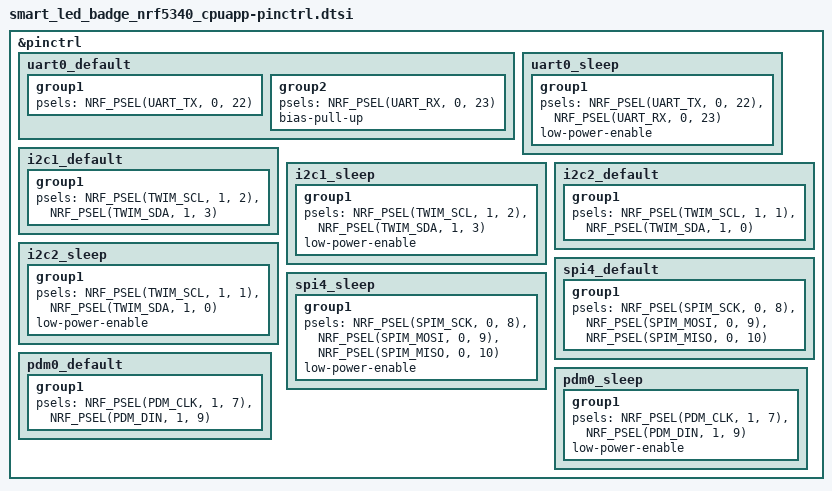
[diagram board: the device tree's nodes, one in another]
/*
 * Copyright (c) 2023 Raytac Corporation
 *
 * SPDX-License-Identifier: Apache-2.0
 *
 * Smart LED Badge Rev A pin control (application core). Pins follow the Rev A
 * schematic (hardware/sheets/mcu_module.kicad_sch). Modified from Zephyr's
 * raytac_mdbt53_db_40 board for this board.
 */

&pinctrl {
	/* Debug UART on test pads: TX P0.22, RX P0.23. */
	uart0_default: uart0_default {
		group1 {
			psels = <NRF_PSEL(UART_TX, 0, 22)>;
		};
		group2 {
			psels = <NRF_PSEL(UART_RX, 0, 23)>;
			bias-pull-up;
		};
	};

	uart0_sleep: uart0_sleep {
		group1 {
			psels = <NRF_PSEL(UART_TX, 0, 22)>,
				<NRF_PSEL(UART_RX, 0, 23)>;
			low-power-enable;
		};
	};

	/* I2C1: ICM-42688-P and BQ25620; 4.7 k pull-ups on the board. */
	i2c1_default: i2c1_default {
		group1 {
			psels = <NRF_PSEL(TWIM_SCL, 1, 2)>,
				<NRF_PSEL(TWIM_SDA, 1, 3)>;
		};
	};

	i2c1_sleep: i2c1_sleep {
		group1 {
			psels = <NRF_PSEL(TWIM_SCL, 1, 2)>,
				<NRF_PSEL(TWIM_SDA, 1, 3)>;
			low-power-enable;
		};
	};

	/* I2C2: NTAG only; pull-ups to NFC_PWR, so the bus is idle without it. */
	i2c2_default: i2c2_default {
		group1 {
			psels = <NRF_PSEL(TWIM_SCL, 1, 1)>,
				<NRF_PSEL(TWIM_SDA, 1, 0)>;
		};
	};

	i2c2_sleep: i2c2_sleep {
		group1 {
			psels = <NRF_PSEL(TWIM_SCL, 1, 1)>,
				<NRF_PSEL(TWIM_SDA, 1, 0)>;
			low-power-enable;
		};
	};

	/* SPIM4 on its dedicated high-speed pins: matrix chain (TLC59283 x2, 74HC595 x4). */
	spi4_default: spi4_default {
		group1 {
			psels = <NRF_PSEL(SPIM_SCK, 0, 8)>,
				<NRF_PSEL(SPIM_MOSI, 0, 9)>,
				<NRF_PSEL(SPIM_MISO, 0, 10)>;
		};
	};

	spi4_sleep: spi4_sleep {
		group1 {
			psels = <NRF_PSEL(SPIM_SCK, 0, 8)>,
				<NRF_PSEL(SPIM_MOSI, 0, 9)>,
				<NRF_PSEL(SPIM_MISO, 0, 10)>;
			low-power-enable;
		};
	};

	/* PDM microphone: CLK P1.07, DIN P1.09. */
	pdm0_default: pdm0_default {
		group1 {
			psels = <NRF_PSEL(PDM_CLK, 1, 7)>,
				<NRF_PSEL(PDM_DIN, 1, 9)>;
		};
	};

	pdm0_sleep: pdm0_sleep {
		group1 {
			psels = <NRF_PSEL(PDM_CLK, 1, 7)>,
				<NRF_PSEL(PDM_DIN, 1, 9)>;
			low-power-enable;
		};
	};
};
